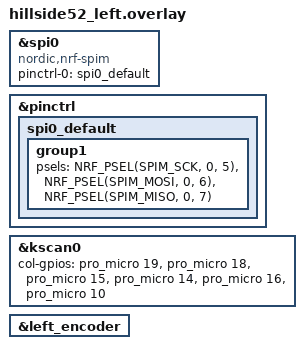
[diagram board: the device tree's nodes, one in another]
/*
 * Copyright (c) 2021-2022 The ZMK Contributors
 *
 * SPDX-License-Identifier: MIT
 */

#include "hillside52.dtsi"

&spi0 {
  compatible = "nordic,nrf-spim";
  status = "okay";
  pinctrl-0 = <&spi0_default>;
  pinctrl-names = "default";
};

&pinctrl {
  spi0_default: spi0_default {
    group1 {
      psels = <NRF_PSEL(SPIM_SCK, 0, 5)>,
              <NRF_PSEL(SPIM_MOSI, 0, 6)>,
              <NRF_PSEL(SPIM_MISO, 0, 7)>;
    };
  };
};

&kscan0 {
  col-gpios
    = <&pro_micro 19 GPIO_ACTIVE_HIGH> // col0 in the schematic
    , <&pro_micro 18 GPIO_ACTIVE_HIGH> // col1 in the schematic
    , <&pro_micro 15 GPIO_ACTIVE_HIGH> // col2 in the schematic
    , <&pro_micro 14 GPIO_ACTIVE_HIGH> // col3 in the schematic
    , <&pro_micro 16 GPIO_ACTIVE_HIGH> // col4 in the schematic
    , <&pro_micro 10 GPIO_ACTIVE_HIGH> // col5 in the schematic
    ;
};

&left_encoder {
  status = "okay";
};
